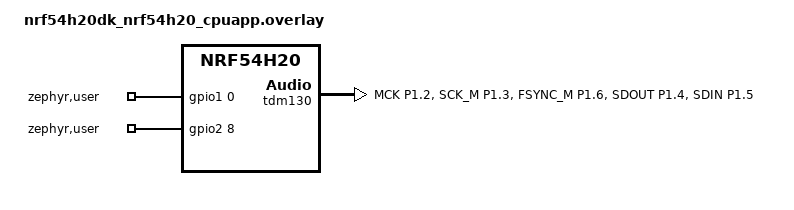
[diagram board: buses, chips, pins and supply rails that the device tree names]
/*
 * Copyright (c) 2025 Nordic Semiconductor ASA
 *
 * SPDX-License-Identifier: LicenseRef-Nordic-5-Clause
 */

/* i2s-node0 is the transmitter/receiver */

/ {
	aliases {
		i2s-node0 = &tdm130;
	};

	zephyr,user {
		gpios = <&gpio1 0 GPIO_ACTIVE_HIGH>,  /* Connect with I2C_MCK */
				<&gpio2 8 GPIO_ACTIVE_HIGH>;  /* Connect with I2S_LRCK_M */
	};
};

&gpio1 {
	status = "okay";
};

&gpio2 {
	status = "okay";
};

&gpiote130 {
	status = "okay";
};

&pinctrl {
	tdm130_default_alt: tdm130_default_alt {
		group1 {
			psels = <NRF_PSEL(TDM_MCK, 1, 2)>,
				<NRF_PSEL(TDM_SCK_M, 1, 3)>,
				<NRF_PSEL(TDM_FSYNC_M, 1, 6)>,
				<NRF_PSEL(TDM_SDOUT, 1, 4)>,  /* I2S_SDOUT connected with I2S_SDIN */
				<NRF_PSEL(TDM_SDIN, 1, 5)>;
		};
	};
};

&tdm130 {
	status = "okay";
	pinctrl-0 = <&tdm130_default_alt>;
	pinctrl-names = "default";
	memory-regions = <&cpuapp_dma_region>;
	mck-frequency = <32000>;
};
